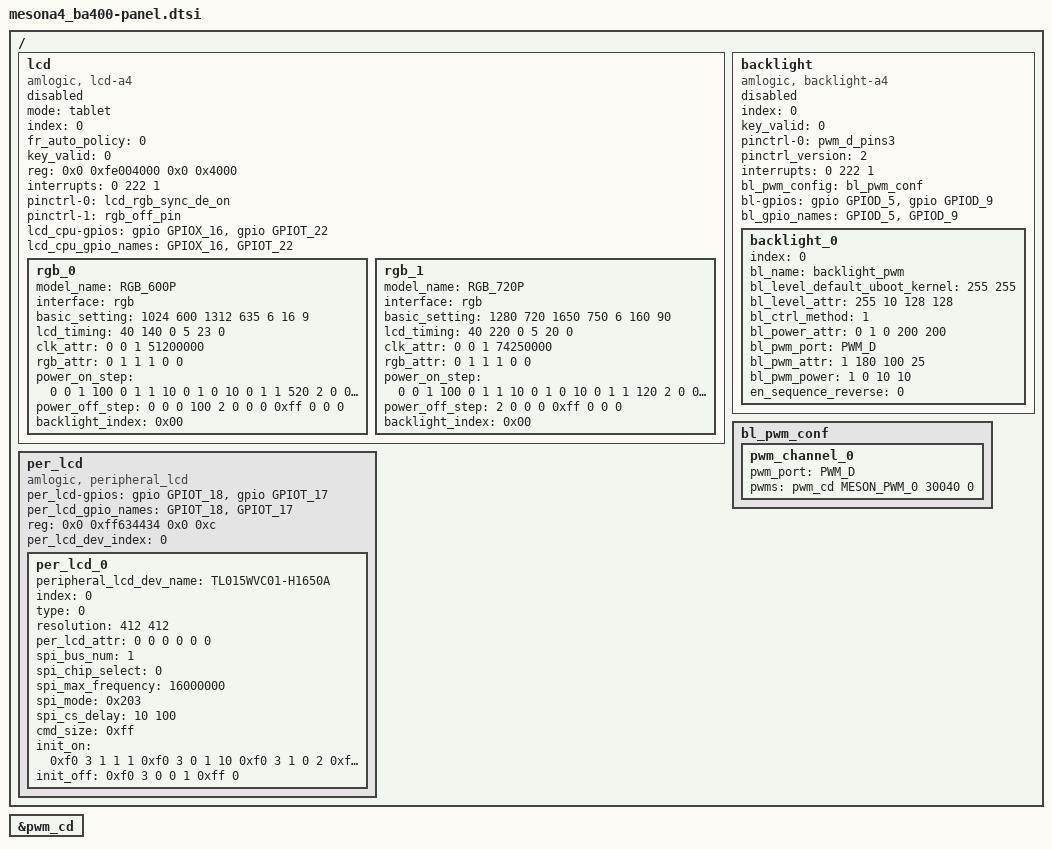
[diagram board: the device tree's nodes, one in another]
// SPDX-License-Identifier: (GPL-2.0+ OR MIT)
/*
 * Copyright (c) 2019 Amlogic, Inc. All rights reserved.
 */

/ {
	lcd {
		compatible = "amlogic, lcd-a4";
		mode = "tablet";
		status = "disabled";
		index = <0>;
		fr_auto_policy = <0>; /* 0=disable, 1=60/50hz, 2=60/50/48hz */
		key_valid = <0>;
		reg = <0x0 0xfe004000 0x0 0x4000>;  /* pin ctrl */
		interrupts = <0 222 1>;
		interrupt-names = "vsync";
		pinctrl-names = "rgb_sync_de_on", "rgb_off";
		pinctrl-0 = <&lcd_rgb_sync_de_on>;
		pinctrl-1 = <&rgb_off_pin>;

		lcd_cpu-gpios = <&gpio GPIOX_16 GPIO_ACTIVE_HIGH /* LCD_PWREN */
						&gpio GPIOT_22 GPIO_ACTIVE_HIGH>; /* LCD_RST */
		lcd_cpu_gpio_names = "GPIOX_16","GPIOT_22";

		rgb_0{
			model_name = "RGB_600P";
			interface = "rgb";
			basic_setting = <1024 600 /*h_active, v_active*/
				1312 635 /*h_period, v_period*/
				6 /*lcd_bits*/
				16 9>; /*screen_widht, screen_height*/
			lcd_timing = <40 140 0 /*hs_width, hs_bp, hs_pol*/
				5 23 0>; /*vs_width, vs_bp, vs_pol*/
			clk_attr = <0 /*fr_adj_type(0=clk, 1=htotal, 2=vtotal)*/
				0 /*clk_ss_level */
				1 /*clk_auto_generate*/
				51200000>; /*pixel_clk(unit in Hz)*/
			rgb_attr = <
				0 /*rgb type*/
				1 /*clk_pol*/
				1 /*de_valid*/
				1 /*sync_valid*/
				0 /*rb_swap*/
				0>; /*bit_swap*/

			/* power step: type, index, value, delay(ms) */
			power_on_step = <
				0 0 1 100
				0 1 1 10
				0 1 0 10
				0 1 1 520
				2 0 0 0   /*signal enable*/
				0xff 0 0 0>; /*ending*/
			power_off_step = <
				0 0 0 100
				2 0 0 0 /*signal disable*/
				0xff 0 0 0>; /*ending*/
			backlight_index = <0x00>;
		};

		rgb_1{
			model_name = "RGB_720P";
			interface = "rgb";
			basic_setting = <1280 720 /*h_active, v_active*/
				1650 750 /*h_period, v_period*/
				6 /*lcd_bits*/
				160 90>; /*screen_widht, screen_height*/
			lcd_timing = <40 220 0 /*hs_width, hs_bp, hs_pol*/
				5 20 0>; /*vs_width, vs_bp, vs_pol*/
			clk_attr = <0 /*fr_adj_type(0=clk, 1=htotal, 2=vtotal)*/
				0 /*clk_ss_level */
				1 /*clk_auto_generate*/
				74250000>; /*pixel_clk(unit in Hz)*/
			rgb_attr = <
				0 /*rgb type*/
				1 /*clk_pol*/
				1 /*de_valid*/
				1 /*sync_valid*/
				0 /*rb_swap*/
				0>; /*bit_swap*/

			/* power step: type, index, value, delay(ms) */
			power_on_step = <
				0 0 1 100
				0 1 1 10
				0 1 0 10
				0 1 1 120
				2 0 0 0   /*signal enable*/
				0xff 0 0 0>; /*ending*/
			power_off_step = <
				2 0 0 0 /*signal disable*/
				0xff 0 0 0>; /*ending*/
			backlight_index = <0x00>;
		};
	};

	backlight{
		compatible = "amlogic, backlight-a4";
		status = "disabled";
		index = <0>;
		key_valid = <0>;
		pinctrl-names = "pwm_on";
		pinctrl-0 = <&pwm_d_pins3>; /* d9 */
		pinctrl_version = <2>; /* for uboot */
		interrupts = <0 222 1>;
		interrupt-names = "vsync";
		bl_pwm_config = <&bl_pwm_conf>;

		/* pwm port: PWM_A, PWM_B, PWM_C, PWM_D, PWM_E, PWM_F, PWM_VS*/
		/* power index:(point gpios_index, 0xff=invalid) */
		/* power value:(0=output low, 1=output high, 2=input) */
		/* power delay:(unit in ms) */
		bl-gpios = <&gpio GPIOD_5 GPIO_ACTIVE_HIGH	/* LCD_BL_EN */
					&gpio GPIOD_9 GPIO_ACTIVE_HIGH>;
		bl_gpio_names = "GPIOD_5", "GPIOD_9";

		backlight_0{
			index = <0>;
			bl_name = "backlight_pwm";
			bl_level_default_uboot_kernel = <255 255>;
			bl_level_attr = <255 10 /*max, min*/
				128 128>; /*mid, mid_mapping*/
			bl_ctrl_method = <1>; /*1=pwm,2=pwm_combo,3=ldim*/
			bl_power_attr = <0 /*en_gpio_index*/
				1 0 /*on_value, off_value*/
				200 200>; /*on_delay(ms), off_delay(ms)*/
			bl_pwm_port = "PWM_D";
			bl_pwm_attr = <1 /*pwm_method(0=negative, 1=positvie)*/
				180 /*pwm_freq(pwm:Hz, pwm_vs:multiple of vs)*/
				100 25>; /*duty_max(%), duty_min(%)*/
			bl_pwm_power = <1 0 /*pwm_gpio_index, pwm_gpio_off*/
				10 10>; /*pwm_on_delay(ms), pwm_off_delay(ms)*/
			en_sequence_reverse = <0>; /* 1 for reverse */
		};
	};

	bl_pwm_conf:bl_pwm_conf{
		pwm_channel_0 {
			pwm_port = "PWM_D";
			pwms = <&pwm_cd MESON_PWM_0 30040 0>;
		};
	};
};

&pwm_cd {
	status = "okay";
};

/ {
	per_lcd {
		compatible = "amlogic, peripheral_lcd";
		status = "okay";

		interrupt-names = "per_lcd_vsync";
		per_lcd-gpios = <
			&gpio GPIOT_18 GPIO_ACTIVE_HIGH /*panel pwr*/
			&gpio GPIOT_17 GPIO_ACTIVE_HIGH>; /*panel rst*/
		per_lcd_gpio_names = "GPIOT_18","GPIOT_17";
		reg = <0x0 0xff634434 0x0 0xc>;
		per_lcd_dev_index = <0>;

		per_lcd_0{
			peripheral_lcd_dev_name = "TL015WVC01-H1650A";
			index = <0>;
			/*0: spi*/
			/*1~3: ireserved for special spi*/
			/*4: mcu 8080*/
			type = <0>;
			resolution = <412 412>; /*h, v*/
			per_lcd_attr = <
				0 /*color fmt: 0=rgb888 1=rgb666 2=rgb565, 3=yuv*/
				0 /*reserved*/
				0 /*reserved*/
				0 /*reserved*/
				0 /*reserved*/
				0>; /*reserved*/
			spi_bus_num = <1>;
			spi_chip_select = <0>;
			spi_max_frequency = <16000000>; /* unit: hz */

			/* see <include/drivers/spi/spi.h>@spi_device.mode */
			spi_mode = <0x203>;
			spi_cs_delay = <10  /* hold_high_delay */
				100>; /* clk_cs_delay (unit: us) */

			cmd_size = <0xff>;
			/* init: (type, data...) */
			/*   type: 0x00=cmd with delay,
			 *         0xc0=cmd,
			 *         0xf0=gpio,
			 *         0xfd=delay,
			 *         0xff=ending
			 */
			/*   data: spi data, fill 0x0 for no use */
			/*   delay: unit ms */
			init_on = <
				0xf0 3 1 1 1
				0xf0 3 0 1 10
				0xf0 3 1 0 2
				0xf0 3 1 1 10

				0x00 8 0x02 0x00 0xFF 0x00 0x20 0x10 0x10 1
				0x00 6 0x02 0x00 0x62 0x00 0x00 1
				0x00 6 0x02 0x00 0x61 0x00 0x00 1
				0x00 6 0x02 0x00 0x5C 0x00 0x00 1
				0x00 6 0x02 0x00 0x58 0x00 0x00 1
				0x00 6 0x02 0x00 0x55 0x00 0x55 1
				0x00 6 0x02 0x00 0x54 0x00 0x44 1
				0x00 6 0x02 0x00 0x51 0x00 0x11 1
				0x00 6 0x02 0x00 0x4B 0x00 0x00 1
				0x00 6 0x02 0x00 0x4A 0x00 0x00 1
				0x00 6 0x02 0x00 0x49 0x00 0x00 1
				0x00 6 0x02 0x00 0x47 0x00 0x77 1
				0x00 6 0x02 0x00 0x46 0x00 0x66 1
				0x00 6 0x02 0x00 0x45 0x00 0x55 1
				0x00 6 0x02 0x00 0x44 0x00 0x44 1
				0x00 6 0x02 0x00 0x43 0x00 0x33 1
				0x00 6 0x02 0x00 0x42 0x00 0x22 1
				0x00 6 0x02 0x00 0x41 0x00 0x11 1
				0x00 6 0x02 0x00 0x37 0x00 0x12 1
				0x00 6 0x02 0x00 0x36 0x00 0x12 1
				0x00 6 0x02 0x00 0x35 0x00 0x11 1
				0x00 6 0x02 0x00 0x34 0x00 0x11 1
				0x00 6 0x02 0x00 0x33 0x00 0x20 1
				0x00 6 0x02 0x00 0x32 0x00 0x00 1
				0x00 6 0x02 0x00 0x31 0x00 0x00 1
				0x00 6 0x02 0x00 0x30 0x00 0x00 1
				0x00 6 0x02 0x00 0x27 0x00 0x12 1
				0x00 6 0x02 0x00 0x26 0x00 0x12 1
				0x00 6 0x02 0x00 0x25 0x00 0x11 1
				0x00 6 0x02 0x00 0x24 0x00 0x11 1
				0x00 6 0x02 0x00 0x23 0x00 0x20 1
				0x00 6 0x02 0x00 0x22 0x00 0x72 1
				0x00 6 0x02 0x00 0x21 0x00 0x82 1
				0x00 6 0x02 0x00 0x20 0x00 0x81 1
				0x00 6 0x02 0x00 0x1B 0x00 0x00 1
				0x00 6 0x02 0x00 0x1A 0x00 0x00 1
				0x00 6 0x02 0x00 0x16 0x00 0x00 1
				0x00 6 0x02 0x00 0x15 0x00 0x00 1
				0x00 6 0x02 0x00 0x11 0x00 0x12 1
				0x00 6 0x02 0x00 0x10 0x00 0x01 1
				0x00 6 0x02 0x00 0x0C 0x00 0x12 1
				0x00 6 0x02 0x00 0x0B 0x00 0x43 1
				0x00 8 0x02 0x00 0xFF 0x00 0x20 0x10 0x11 1
				0x00 6 0x02 0x00 0x6A 0x00 0x10 1
				0x00 6 0x02 0x00 0x69 0x00 0x03 1
				0x00 6 0x02 0x00 0x68 0x00 0x34 1
				0x00 6 0x02 0x00 0x67 0x00 0x04 1
				0x00 6 0x02 0x00 0x66 0x00 0x38 1
				0x00 6 0x02 0x00 0x65 0x00 0x03 1
				0x00 6 0x02 0x00 0x64 0x00 0x34 1
				0x00 6 0x02 0x00 0x63 0x00 0x04 1
				0x00 6 0x02 0x00 0x62 0x00 0x38 1
				0x00 6 0x02 0x00 0x61 0x00 0x03 1
				0x00 6 0x02 0x00 0x60 0x00 0x01 1
				0x00 6 0x02 0x00 0x55 0x00 0x06 1
				0x00 6 0x02 0x00 0x50 0x00 0x01 1
				0x00 6 0x02 0x00 0x30 0x00 0xEE 1
				0x00 6 0x02 0x00 0x1E 0x00 0x88 1
				0x00 6 0x02 0x00 0x1D 0x00 0x88 1
				0x00 6 0x02 0x00 0x1C 0x00 0x88 1
				0x00 6 0x02 0x00 0x16 0x00 0x99 1
				0x00 6 0x02 0x00 0x15 0x00 0x99 1
				0x00 6 0x02 0x00 0x14 0x00 0x34 1
				0x00 6 0x02 0x00 0x13 0x00 0xf0 1
				0x00 6 0x02 0x00 0x0c 0x00 0xF0 1
				0x00 6 0x02 0x00 0x0B 0x00 0xF0 1
				0x00 6 0x02 0x00 0x0A 0x00 0x00 1
				0x00 6 0x02 0x00 0x09 0x00 0x00 1
				0x00 6 0x02 0x00 0x08 0x00 0x70 1
				0x00 8 0x02 0x00 0xFF 0x00 0x20 0x10 0x12 1
				0x00 6 0x02 0x00 0x36 0x00 0xA0 1
				0x00 6 0x02 0x00 0x2E 0x00 0x1e 1
				0x00 6 0x02 0x00 0x2D 0x00 0x2D 1
				0x00 6 0x02 0x00 0x2C 0x00 0x26 1
				0x00 6 0x02 0x00 0x2B 0x00 0x1e 1
				0x00 6 0x02 0x00 0x2A 0x00 0x2D 1
				0x00 6 0x02 0x00 0x21 0x00 0x70 1
				0x00 6 0x02 0x00 0x1F 0x00 0xE6 1
				0x00 6 0x02 0x00 0x18 0x00 0x00 1
				0x00 6 0x02 0x00 0x15 0x00 0x0F 1
				0x00 6 0x02 0x00 0x12 0x00 0x89 1
				0x00 6 0x02 0x00 0x10 0x00 0x0F 1
				0x00 6 0x02 0x00 0x0D 0x00 0x66 1
				0x00 6 0x02 0x00 0x06 0x00 0x06 1
				0x00 6 0x02 0x00 0x00 0x00 0xCC 1
				0x00 8 0x02 0x00 0xFF 0x00 0x20 0x10 0x15 1
				0x00 6 0x02 0x00 0x2F 0x00 0x01 1
				0x00 6 0x02 0x00 0x2E 0x00 0x01 1
				0x00 6 0x02 0x00 0x2D 0x00 0x35 1
				0x00 6 0x02 0x00 0x2C 0x00 0x34 1
				0x00 6 0x02 0x00 0x2B 0x00 0x32 1
				0x00 6 0x02 0x00 0x2A 0x00 0x33 1
				0x00 6 0x02 0x00 0x29 0x00 0x1D 1
				0x00 6 0x02 0x00 0x28 0x00 0x1B 1
				0x00 6 0x02 0x00 0x27 0x00 0x19 1
				0x00 6 0x02 0x00 0x26 0x00 0x17 1
				0x00 6 0x02 0x00 0x25 0x00 0x09 1
				0x00 6 0x02 0x00 0x24 0x00 0x05 1
				0x00 6 0x02 0x00 0x23 0x00 0x00 1
				0x00 6 0x02 0x00 0x22 0x00 0x00 1
				0x00 6 0x02 0x00 0x21 0x00 0x00 1
				0x00 6 0x02 0x00 0x20 0x00 0x00 1
				0x00 6 0x02 0x00 0x0F 0x00 0x01 1
				0x00 6 0x02 0x00 0x0E 0x00 0x01 1
				0x00 6 0x02 0x00 0x0D 0x00 0x35 1
				0x00 6 0x02 0x00 0x0C 0x00 0x34 1
				0x00 6 0x02 0x00 0x0B 0x00 0x32 1
				0x00 6 0x02 0x00 0x0A 0x00 0x33 1
				0x00 6 0x02 0x00 0x09 0x00 0x16 1
				0x00 6 0x02 0x00 0x08 0x00 0x18 1
				0x00 6 0x02 0x00 0x07 0x00 0x1A 1
				0x00 6 0x02 0x00 0x06 0x00 0x1C 1
				0x00 6 0x02 0x00 0x05 0x00 0x04 1
				0x00 6 0x02 0x00 0x04 0x00 0x08 1
				0x00 6 0x02 0x00 0x03 0x00 0x00 1
				0x00 6 0x02 0x00 0x02 0x00 0x00 1
				0x00 6 0x02 0x00 0x01 0x00 0x00 1
				0x00 6 0x02 0x00 0x00 0x00 0x00 1
				0x00 8 0x02 0x00 0xFF 0x00 0x20 0x10 0x16 1
				0x00 6 0x02 0x00 0x2F 0x00 0x01 1
				0x00 6 0x02 0x00 0x2E 0x00 0x01 1
				0x00 6 0x02 0x00 0x2D 0x00 0x35 1
				0x00 6 0x02 0x00 0x2C 0x00 0x34 1
				0x00 6 0x02 0x00 0x2B 0x00 0x32 1
				0x00 6 0x02 0x00 0x2A 0x00 0x33 1
				0x00 6 0x02 0x00 0x29 0x00 0x1C 1
				0x00 6 0x02 0x00 0x28 0x00 0x1A 1
				0x00 6 0x02 0x00 0x27 0x00 0x18 1
				0x00 6 0x02 0x00 0x26 0x00 0x16 1
				0x00 6 0x02 0x00 0x25 0x00 0x08 1
				0x00 6 0x02 0x00 0x24 0x00 0x04 1
				0x00 6 0x02 0x00 0x23 0x00 0x00 1
				0x00 6 0x02 0x00 0x22 0x00 0x00 1
				0x00 6 0x02 0x00 0x21 0x00 0x00 1
				0x00 6 0x02 0x00 0x20 0x00 0x00 1
				0x00 6 0x02 0x00 0x0F 0x00 0x01 1
				0x00 6 0x02 0x00 0x0E 0x00 0x01 1
				0x00 6 0x02 0x00 0x0D 0x00 0x35 1
				0x00 6 0x02 0x00 0x0C 0x00 0x34 1
				0x00 6 0x02 0x00 0x0B 0x00 0x32 1
				0x00 6 0x02 0x00 0x0A 0x00 0x33 1
				0x00 6 0x02 0x00 0x09 0x00 0x17 1
				0x00 6 0x02 0x00 0x08 0x00 0x19 1
				0x00 6 0x02 0x00 0x07 0x00 0x1B 1
				0x00 6 0x02 0x00 0x06 0x00 0x1D 1
				0x00 6 0x02 0x00 0x05 0x00 0x05 1
				0x00 6 0x02 0x00 0x04 0x00 0x09 1
				0x00 6 0x02 0x00 0x03 0x00 0x00 1
				0x00 6 0x02 0x00 0x02 0x00 0x00 1
				0x00 6 0x02 0x00 0x01 0x00 0x00 1
				0x00 6 0x02 0x00 0x00 0x00 0x00 1
				0x00 8 0x02 0x00 0xFF 0x00 0x20 0x10 0x17 1
				0x00 6 0x02 0x00 0x39 0x00 0x3c 1
				0x00 6 0x02 0x00 0x37 0x00 0x00 1
				0x00 6 0x02 0x00 0x1F 0x00 0x80 1
				0x00 6 0x02 0x00 0x1A 0x00 0x80 1
				0x00 6 0x02 0x00 0x18 0x00 0xA0 1
				0x00 6 0x02 0x00 0x16 0x00 0x12 1
				0x00 6 0x02 0x00 0x14 0x00 0xAA 1
				0x00 6 0x02 0x00 0x11 0x00 0xAA 1
				0x00 6 0x02 0x00 0x10 0x00 0x0E 1
				0x00 6 0x02 0x00 0x0B 0x00 0xC3 1
				0x00 8 0x02 0x00 0xFF 0x00 0x20 0x10 0x18 1
				0x00 6 0x02 0x00 0x3A 0x00 0x01 1
				0x00 6 0x02 0x00 0x1F 0x00 0x02 1
				0x00 6 0x02 0x00 0x01 0x00 0x01 1
				0x00 6 0x02 0x00 0x00 0x00 0x1E 1
				0x00 8 0x02 0x00 0xFF 0x00 0x20 0x10 0x2D 1
				0x00 6 0x02 0x00 0x02 0x00 0x00  1
				0x00 6 0x02 0x00 0x01 0x00 0x3E 1
				0x00 8 0x02 0x00 0xff 0x00 0x20 0x10 0x31 1
				0x00 6 0x02 0x00 0x39 0x00 0xf0 1
				0x00 6 0x02 0x00 0x38 0x00 0x03 1
				0x00 6 0x02 0x00 0x37 0x00 0xe8 1
				0x00 6 0x02 0x00 0x36 0x00 0x03 1
				0x00 6 0x02 0x00 0x35 0x00 0xCF 1
				0x00 6 0x02 0x00 0x34 0x00 0x03 1
				0x00 6 0x02 0x00 0x33 0x00 0xBA 1
				0x00 6 0x02 0x00 0x32 0x00 0x03 1
				0x00 6 0x02 0x00 0x31 0x00 0xA2 1
				0x00 6 0x02 0x00 0x30 0x00 0x03 1
				0x00 6 0x02 0x00 0x2f 0x00 0x95 1
				0x00 6 0x02 0x00 0x2e 0x00 0x03 1
				0x00 6 0x02 0x00 0x2d 0x00 0x7e 1
				0x00 6 0x02 0x00 0x2c 0x00 0x03 1
				0x00 6 0x02 0x00 0x2b 0x00 0x62 1
				0x00 6 0x02 0x00 0x2a 0x00 0x03 1
				0x00 6 0x02 0x00 0x29 0x00 0x44 1
				0x00 6 0x02 0x00 0x28 0x00 0x03 1
				0x00 6 0x02 0x00 0x27 0x00 0xfc 1
				0x00 6 0x02 0x00 0x26 0x00 0x02 1
				0x00 6 0x02 0x00 0x25 0x00 0xd0 1
				0x00 6 0x02 0x00 0x24 0x00 0x02 1
				0x00 6 0x02 0x00 0x23 0x00 0x98 1
				0x00 6 0x02 0x00 0x22 0x00 0x02 1
				0x00 6 0x02 0x00 0x21 0x00 0x6f 1
				0x00 6 0x02 0x00 0x20 0x00 0x02 1
				0x00 6 0x02 0x00 0x1f 0x00 0x32 1
				0x00 6 0x02 0x00 0x1e 0x00 0x02 1
				0x00 6 0x02 0x00 0x1d 0x00 0xf6 1
				0x00 6 0x02 0x00 0x1c 0x00 0x01 1
				0x00 6 0x02 0x00 0x1b 0x00 0xb8 1
				0x00 6 0x02 0x00 0x1a 0x00 0x01 1
				0x00 6 0x02 0x00 0x19 0x00 0x6E 1
				0x00 6 0x02 0x00 0x18 0x00 0x01 1
				0x00 6 0x02 0x00 0x17 0x00 0x41 1
				0x00 6 0x02 0x00 0x16 0x00 0x01 1
				0x00 6 0x02 0x00 0x15 0x00 0xfd 1
				0x00 6 0x02 0x00 0x14 0x00 0x00 1
				0x00 6 0x02 0x00 0x13 0x00 0xCf 1
				0x00 6 0x02 0x00 0x12 0x00 0x00 1
				0x00 6 0x02 0x00 0x11 0x00 0x98 1
				0x00 6 0x02 0x00 0x10 0x00 0x00 1
				0x00 6 0x02 0x00 0x0f 0x00 0x89 1
				0x00 6 0x02 0x00 0x0e 0x00 0x00 1
				0x00 6 0x02 0x00 0x0d 0x00 0x79 1
				0x00 6 0x02 0x00 0x0c 0x00 0x00 1
				0x00 6 0x02 0x00 0x0b 0x00 0x67 1
				0x00 6 0x02 0x00 0x0a 0x00 0x00 1
				0x00 6 0x02 0x00 0x09 0x00 0x55 1
				0x00 6 0x02 0x00 0x08 0x00 0x00 1
				0x00 6 0x02 0x00 0x07 0x00 0x3F 1
				0x00 6 0x02 0x00 0x06 0x00 0x00 1
				0x00 6 0x02 0x00 0x05 0x00 0x28 1
				0x00 6 0x02 0x00 0x04 0x00 0x00 1
				0x00 6 0x02 0x00 0x03 0x00 0x0E 1
				0x00 6 0x02 0x00 0x02 0x00 0x00 1
				0x00 8 0x02 0x00 0xff 0x00 0x20 0x10 0x32 1
				0x00 6 0x02 0x00 0x39 0x00 0xf0 1
				0x00 6 0x02 0x00 0x38 0x00 0x03 1
				0x00 6 0x02 0x00 0x37 0x00 0xe8 1
				0x00 6 0x02 0x00 0x36 0x00 0x03 1
				0x00 6 0x02 0x00 0x35 0x00 0xCF 1
				0x00 6 0x02 0x00 0x34 0x00 0x03 1
				0x00 6 0x02 0x00 0x33 0x00 0xBA 1
				0x00 6 0x02 0x00 0x32 0x00 0x03 1
				0x00 6 0x02 0x00 0x31 0x00 0xA2 1
				0x00 6 0x02 0x00 0x30 0x00 0x03 1
				0x00 6 0x02 0x00 0x2f 0x00 0x95 1
				0x00 6 0x02 0x00 0x2e 0x00 0x03 1
				0x00 6 0x02 0x00 0x2d 0x00 0x7e 1
				0x00 6 0x02 0x00 0x2c 0x00 0x03 1
				0x00 6 0x02 0x00 0x2b 0x00 0x62 1
				0x00 6 0x02 0x00 0x2a 0x00 0x03 1
				0x00 6 0x02 0x00 0x29 0x00 0x44 1
				0x00 6 0x02 0x00 0x28 0x00 0x03 1
				0x00 6 0x02 0x00 0x27 0x00 0xfc 1
				0x00 6 0x02 0x00 0x26 0x00 0x02 1
				0x00 6 0x02 0x00 0x25 0x00 0xd0 1
				0x00 6 0x02 0x00 0x24 0x00 0x02 1
				0x00 6 0x02 0x00 0x23 0x00 0x98 1
				0x00 6 0x02 0x00 0x22 0x00 0x02 1
				0x00 6 0x02 0x00 0x21 0x00 0x6f 1
				0x00 6 0x02 0x00 0x20 0x00 0x02 1
				0x00 6 0x02 0x00 0x1f 0x00 0x32 1
				0x00 6 0x02 0x00 0x1e 0x00 0x02 1
				0x00 6 0x02 0x00 0x1d 0x00 0xf6 1
				0x00 6 0x02 0x00 0x1c 0x00 0x01 1
				0x00 6 0x02 0x00 0x1b 0x00 0xb8 1
				0x00 6 0x02 0x00 0x1a 0x00 0x01 1
				0x00 6 0x02 0x00 0x19 0x00 0x6E 1
				0x00 6 0x02 0x00 0x18 0x00 0x01 1
				0x00 6 0x02 0x00 0x17 0x00 0x41 1
				0x00 6 0x02 0x00 0x16 0x00 0x01 1
				0x00 6 0x02 0x00 0x15 0x00 0xfd 1
				0x00 6 0x02 0x00 0x14 0x00 0x00 1
				0x00 6 0x02 0x00 0x13 0x00 0xCf 1
				0x00 6 0x02 0x00 0x12 0x00 0x00 1
				0x00 6 0x02 0x00 0x11 0x00 0x98 1
				0x00 6 0x02 0x00 0x10 0x00 0x00 1
				0x00 6 0x02 0x00 0x0f 0x00 0x89 1
				0x00 6 0x02 0x00 0x0e 0x00 0x00 1
				0x00 6 0x02 0x00 0x0d 0x00 0x79 1
				0x00 6 0x02 0x00 0x0c 0x00 0x00 1
				0x00 6 0x02 0x00 0x0b 0x00 0x67 1
				0x00 6 0x02 0x00 0x0a 0x00 0x00 1
				0x00 6 0x02 0x00 0x09 0x00 0x55 1
				0x00 6 0x02 0x00 0x08 0x00 0x00 1
				0x00 6 0x02 0x00 0x07 0x00 0x3F 1
				0x00 6 0x02 0x00 0x06 0x00 0x00 1
				0x00 6 0x02 0x00 0x05 0x00 0x28 1
				0x00 6 0x02 0x00 0x04 0x00 0x00 1
				0x00 6 0x02 0x00 0x03 0x00 0x0E 1
				0x00 6 0x02 0x00 0x02 0x00 0x00 1
				0x00 8 0x02 0x00 0xff 0x00 0x20 0x10 0x40 1
				0x00 6 0x02 0x00 0x86 0x00 0x00 1
				0x00 6 0x02 0x00 0x83 0x00 0xC4 1
				0x00 8 0x02 0x00 0xFF 0x00 0x20 0x10 0x42 1
				0x00 6 0x02 0x00 0x06 0x00 0x03 1
				0x00 6 0x02 0x00 0x05 0x00 0x3D 1
				0x00 8 0x02 0x00 0xFF 0x00 0x20 0x10 0x43 1
				0x00 6 0x02 0x00 0x03 0x00 0x04 1
				0x00 8 0x02 0x00 0xFF 0x00 0x20 0x10 0x45 1
				0x00 6 0x02 0x00 0x03 0x00 0x9C 1
				0x00 6 0x02 0x00 0x01 0x00 0x9C 1

				0x00 8 0x02 0x00 0xFF 0x00 0x20 0x10 0xA0 1
				0x00 6 0x02 0x00 0x08 0x00 0xE6 1
				0x00 8 0x02 0x00 0xFF 0x00 0x20 0x10 0x00 1
				0x00 9 0x02 0x00 0x2A 0x00 0x00 0x00 0x01 0x9B 1
				0x00 9 0x02 0x00 0x2B 0x00 0x00 0x00 0x01 0x9B 1
				0x00 6 0x02 0x00 0x35 0x00 0x00 1

				/* 0x05=RGB565 ,0x07=RGB888, 0x06=RGB666 */
				0x00 6 0x02 0x00 0x3A 0x00 0x07 5

				0x00 5 0x02 0x00 0x11 0x00 100
				0x00 5 0x02 0x00 0x29 0x00 100

				0xff 0>;
			init_off = <
				0xf0 3 0 0 1
				0xff 0>;
		};
	};
};
